# AC33Mx128 register map
Vendor: ABOV Semiconductor Co., Ltd.; File version: 0.6
CPU: CM3 r1p0, little endian, no MPU, no FPU, 3 interrupt priority bits
Registers are 32-bit, read-write, reset 0x0 unless marked. A register's access mark holds for its fields unless they carry their own. Offsets are from the block's base; [hi:lo] are bit positions.

## T0 — 16-BIT TIMER
Base 0x40003000
Same registers: T1 0x40003020, T2 0x40003040, T3 0x40003060, T8 0x40003100, T9 0x40003120
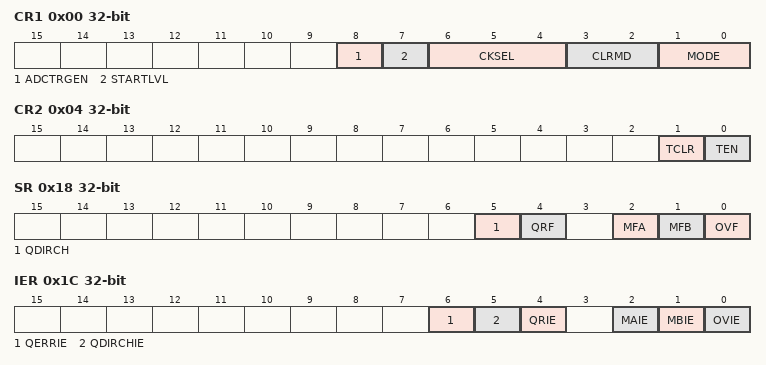
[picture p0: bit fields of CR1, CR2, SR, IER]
0x00 CR1 — Timer n Control Register 1
  [8] ADCTRGEN
  [7] STARTLVL
  [6:4] CKSEL — counter clock source select
  [3:2] CLRMD — clear select when capture mode
  [1:0] MODE — Timer operatin mode control
0x04 CR2 — Timer n Control Register 2
  [1] TCLR — Timer register clear
  [0] TEN — Timer enable bit
0x08 PRS — Timer n Prescaler Register
  [9:0] PRS — Prescaler value of count clock
0x0C GRA — Timer n General Register A
  [15:0] GRA
0x10 GRB — Timer n General Register B
  [15:0] GRB
0x14 CNT — Timer n Count Register
  [15:0] CNT
0x18 SR — Timer n Status Register
  [5] QDIRCH — Quadrature direction change
  [4] QRF — Quadrature revolution flag
  [2] MFA — Match register A Flag
  [1] MFB — MATCH register B flag
  [0] OVF — counter overflow falg
0x1C IER wo — Timer n Interrupt Enable Register
  [6] QERRIE — Quadrature decoder error interrupt enable
  [5] QDIRCHIE — Quadrature direction change interrupt enable
  [4] QRIE — Quadrature revolution interrupt enable
  [2] MAIE — GRA Match interrupt enablee
  [1] MBIE — GRB Match interrupt enable
  [0] OVIE — Counter overflow interrupt enable

## TGECR — Timer Group Encoder Control Register
Base 0x40003140
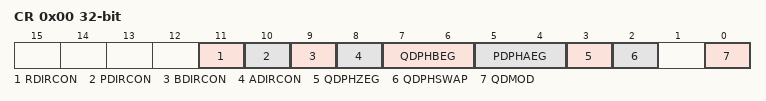
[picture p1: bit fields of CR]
0x00 CR — Timer Group Encoder Control Register
  [11] RDIRCON — Revolution counter direction control
  [10] PDIRCON — Position counter direction control
  [9] BDIRCON — Phase B counter direction control
  [8] ADIRCON — PHASE A counter direction control
  [7:6] QDPHBEG — Quadrature mode phase B count for position count
  [5:4] PDPHAEG — Quadrature mode phase A count for position count
  [3] QDPHZEG — Quadrature mode phase Z count for Revolution
  [2] QDPHSWAP — Quadrature mode phase Z count for Revolution
  [0] QDMOD — Quadrature decoder mode

## U0 — UNIVERSAL ASYNCHRONOUS RECEIVER/TRANSMITTER
Base 0x40008000
Same registers: U1 0x40008100, U2 0x40008200, U3 0x40008300
0x00 RBR ro — Receive Buffer Register
  [7:0] RBR — recevied/transmit data
0x00 THR wo — Transmit Data Hold Register
  [7:0] THR — recevied/transmit data
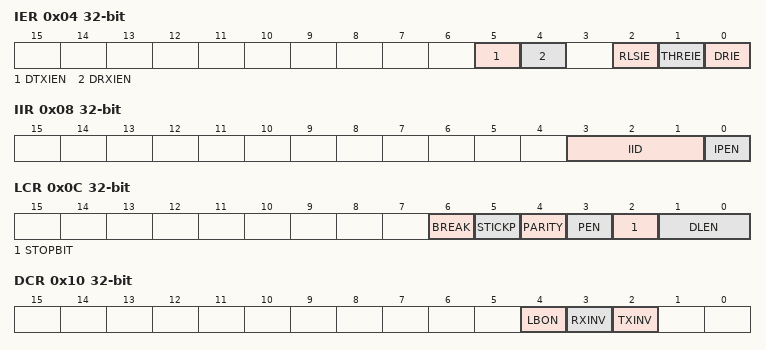
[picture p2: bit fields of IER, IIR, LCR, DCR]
0x04 IER — UART Interrupt Enable Register
  [5] DTXIEN — DMA transmit done interrupt enable
  [4] DRXIEN — DMA Receiver line status interrupt enable
  [2] RLSIE — receiver line status interrupt enable
  [1] THREIE — Transmit holding register empty interrupt enable
  [0] DRIE — Data receive interrupt enable
0x08 IIR — UART Interrupt ID Register
  [3:1] IID — Interrupt source ID
  [0] IPEN — Interrupt pending bit
0x0C LCR — UART Line Control Register
  [6] BREAK
  [5] STICKP — STICK
  [4] PARITY
  [3] PEN — parity bit transfer enable
  [2] STOPBIT
  [1:0] DLEN — Data length in one transfer word
0x10 DCR — UART Data Control Register
  [4] LBON — Local loopback test mode enable
  [3] RXINV — Rx Data Inversion selection
  [2] TXINV — TX Data Inversion selection
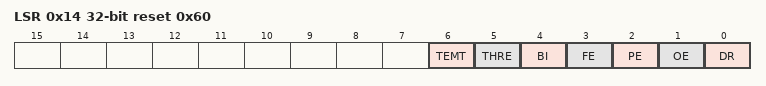
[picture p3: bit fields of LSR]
0x14 LSR reset 0x60 — UART Line Status Register
  [6] TEMT — Transmit empty
  [5] THRE — Transmit holding register empty
  [4] BI — break condition indication bit
  [3] FE — frame error
  [2] PE — parity error
  [1] OE — overrun error
  [0] DR — Data recevied
0x20 BDR — Baud rate Divisor Latch Register
  [15:0] BDR — baudrate setting
0x24 BFR — Baud rate Fraction Counter Register
  [7:0] BFR — Fraction counter value
0x30 IDTR — Inter-frame Delay Time Register
  [2:0] WAITVAL — wait time is decied by this value

## SP0 — SERIAL PERIPHERAL INTERFACE
Base 0x40009000
Same registers: SP1 0x40009100
0x00 RDR ro — SPI n Receive Data Register
  [15:0] RDR — Data
0x00 TDR wo — SPI n Transmit Data Register
  [15:0] TDR — Data
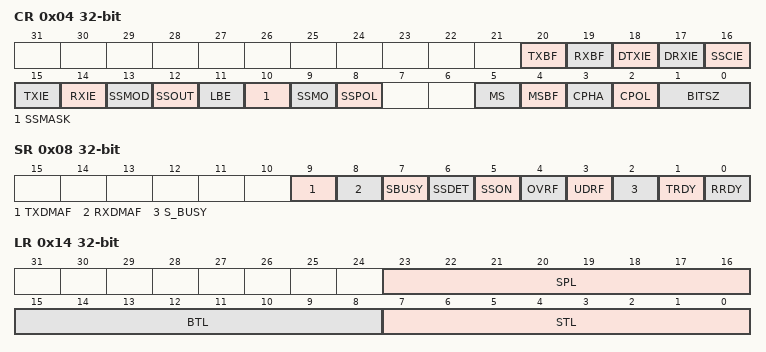
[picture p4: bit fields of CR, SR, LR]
0x04 CR — SPI n Control Register
  [20] TXBF — TX Buffer flushing enable bitr
  [19] RXBF — Recieve buffer flushing enable
  [18] DTXIE — DMA TX Done Interrupt enable bit
  [17] DRXIE — DMA Rx Deone Interrupt enable bit
  [16] SSCIE — SSn Edge Chagne Interrupt enable bit
  [15] TXIE — Transmit interrupt enable bit
  [14] RXIE — Receive interrupt enable bit
  [13] SSMOD — SS Auto/Manual Output select bit
  [12] SSOUT — SS output signal select bit
  [11] LBE — Loop-back mode select bit in master mode
  [10] SSMASK — SS Signal masking bit in slave mode
  [9] SSMO — SS output signal select bit
  [8] SSPOL — SS Signal polarity select bit
  [5] MS — master/slaver select bit
  [4] MSBF — MSB/LSB transmit select bit
  [3] CPHA — SPI clock phase bit
  [2] CPOL — SPI clock polarity bit
  [1:0] BITSZ — Transmit/receive Data bits select bit
0x08 SR — SPI n Status Register
  [9] TXDMAF — DMA transmit Operation complete flag
  [8] RXDMAF — DMA receive Operation complete flag
  [7] SBUSY ro — Transmit/Receive Operation flag
  [6] SSDET — The rising edge of SS detect flag
  [5] SSON — SS signal status flag
  [4] OVRF — receive overrun error flag
  [3] UDRF — transmit underrun error flag
  [2] S_BUSY ro — transmit/receive operation flag
  [1] TRDY ro — Transmit buffer empty flag
  [0] RRDY ro — receive buffer ready flag
0x0C BR — SPI n Baud Rate Register
  [15:0] BR — buadrate
0x10 EN — SPI n Enable register
  [0] ENABLE — SPI ENABLE bit
0x14 LR — SPI n delay Length Register
  [23:16] SPL — Stop delay length
  [15:8] BTL — Burst delay length
  [7:0] STL — Start delay length
